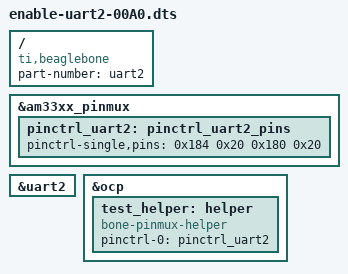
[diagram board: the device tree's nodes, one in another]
/*
 * Copyright (C) 2012 Texas Instruments Incorporated - http://www.ti.com/
 *
 * This program is free software; you can redistribute it and/or modify
 * it under the terms of the GNU General Public License version 2 as
 * published by the Free Software Foundation.
 */
/dts-v1/;
/plugin/;

/ {
    compatible = "ti,beaglebone", "ti,beaglebone-black";

    /* identification */
    part-number = "uart2";

    fragment@0 {
        target = <&am33xx_pinmux>;
        __overlay__ {
            pinctrl_uart2: pinctrl_uart2_pins {
                pinctrl-single,pins = <					 				   
                        0x184 0x20  /* P9.24 uart1_txd.uasrt1_txd OUTPUT */
                        0x180 0x20  /* P9.26 uart1_rxd.uart1_rxd INPUT */
                >;
            };
        };
    };

	fragment@1{
		target = <&uart2>;
		__overlay__ {
			status			= "okay";
		};
	};

    fragment@2 {
        target = <&ocp>;
        __overlay__ {
            test_helper: helper {
                compatible = "bone-pinmux-helper";
                pinctrl-names = "default";
                pinctrl-0 = <&pinctrl_uart2>;
                status = "okay";
            };
        };
    };
};
